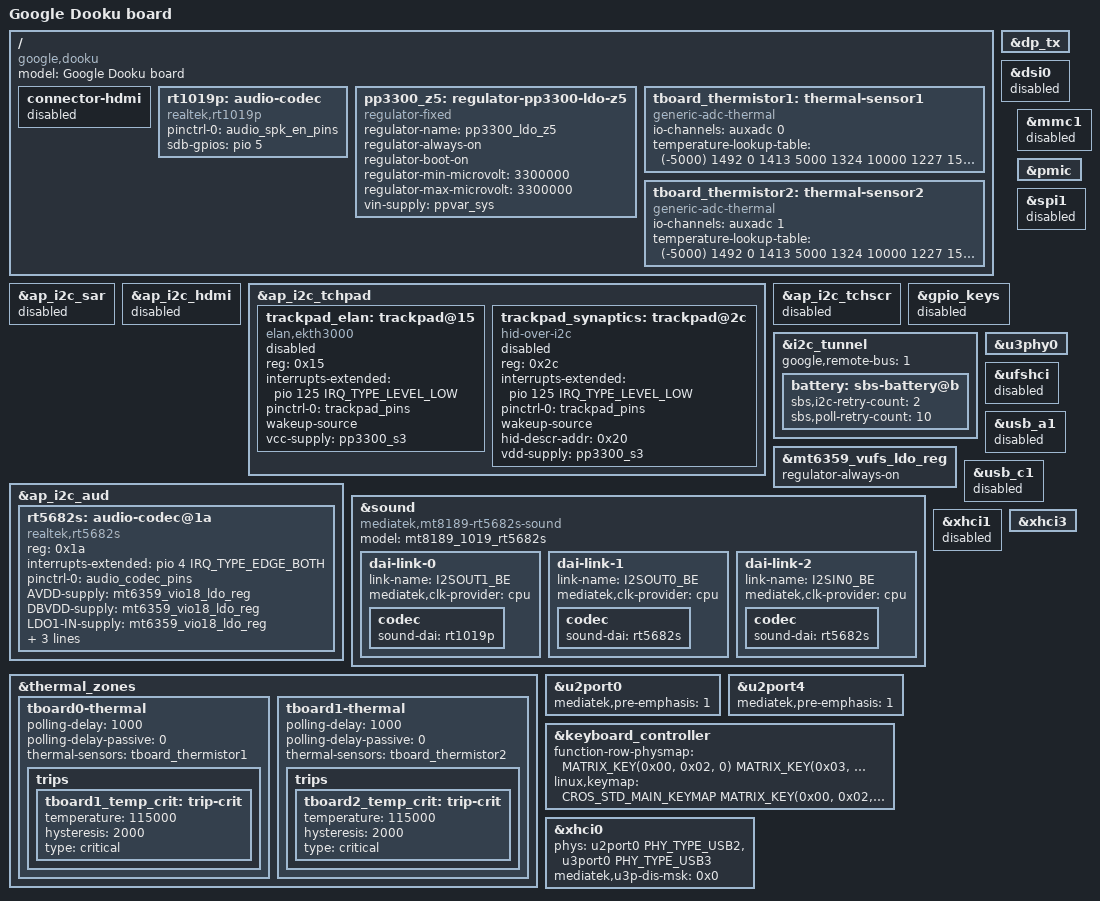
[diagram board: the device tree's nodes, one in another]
// SPDX-License-Identifier: (GPL-2.0 OR MIT)
/*
 * Copyright (C) 2025 Google Inc.
 */
/dts-v1/;
#include "mt8189-skywalker.dtsi"

/ {
	model = "Google Dooku board";
	compatible = "google,dooku", "mediatek,mt8189";

	connector-hdmi {
		status = "disabled";
	};

	/delete-node/ rt9123;

	rt1019p: audio-codec {
		compatible = "realtek,rt1019p";
		#sound-dai-cells = <0>;
		pinctrl-names = "default";
		pinctrl-0 = <&audio_spk_en_pins>;
		sdb-gpios = <&pio 5 GPIO_ACTIVE_HIGH>;
	};

	/* system wide LDO 3.3V power rail */
	pp3300_z5: regulator-pp3300-ldo-z5 {
		compatible = "regulator-fixed";
		regulator-name = "pp3300_ldo_z5";
		regulator-always-on;
		regulator-boot-on;
		regulator-min-microvolt = <3300000>;
		regulator-max-microvolt = <3300000>;
		vin-supply = <&ppvar_sys>;
	};

	tboard_thermistor1: thermal-sensor1 {
		compatible = "generic-adc-thermal";
		#thermal-sensor-cells = <0>;
		io-channels = <&auxadc 0>;
		io-channel-names = "sensor-channel";
		temperature-lookup-table = <    (-5000) 1492
						0 1413
						5000 1324
						10000 1227
						15000 1121
						20000 1017
						25000 900
						30000 797
						35000 698
						40000 606
						45000 522
						50000 449
						55000 383
						60000 327
						65000 278
						70000 236
						75000 201
						80000 171
						85000 145
						90000 163
						95000 124
						100000 91
						105000 78
						110000 67
						115000 58
						120000 50
						125000 44>;
	};

	tboard_thermistor2: thermal-sensor2 {
		compatible = "generic-adc-thermal";
		#thermal-sensor-cells = <0>;
		io-channels = <&auxadc 1>;
		io-channel-names = "sensor-channel";
		temperature-lookup-table = <    (-5000) 1492
						0 1413
						5000 1324
						10000 1227
						15000 1121
						20000 1017
						25000 900
						30000 797
						35000 698
						40000 606
						45000 522
						50000 449
						55000 383
						60000 327
						65000 278
						70000 236
						75000 201
						80000 171
						85000 145
						90000 163
						95000 124
						100000 91
						105000 78
						110000 67
						115000 58
						120000 50
						125000 44>;
	};
};

&ap_i2c_sar {
	status = "disabled";
};

&ap_i2c_hdmi {
	status = "disabled";
};

&ap_i2c_tchpad {
	/delete-node/ trackpad@15;

	trackpad_elan: trackpad@15 {
		compatible = "elan,ekth3000";
		reg = <0x15>;
		interrupts-extended = <&pio 125 IRQ_TYPE_LEVEL_LOW>;
		pinctrl-names = "default";
		pinctrl-0 = <&trackpad_pins>;
		wakeup-source;
		vcc-supply = <&pp3300_s3>;
		status = "fail-needs-probe";
	};

	trackpad_synaptics: trackpad@2c  {
		compatible = "hid-over-i2c";
		reg = <0x2c>;
		interrupts-extended = <&pio 125 IRQ_TYPE_LEVEL_LOW>;
		pinctrl-names = "default";
		pinctrl-0 = <&trackpad_pins>;
		wakeup-source;
		hid-descr-addr = <0x20>;
		vdd-supply = <&pp3300_s3>;
		status = "fail-needs-probe";
	};
};

&ap_i2c_tchscr {
	status = "disabled";

	/delete-node/ touchscreen@41;
};

&dp_tx {
	/delete-property/ mediatek,phy-flip-gpios;
};

&dsi0 {
	status = "disabled";
};

&ap_i2c_aud {
	/delete-node/ audio-codec@1a;

	rt5682s: audio-codec@1a {
		compatible = "realtek,rt5682s";
		reg = <0x1a>;
		interrupts-extended = <&pio 4 IRQ_TYPE_EDGE_BOTH>;
		pinctrl-names = "default";
		pinctrl-0 = <&audio_codec_pins>;
		#sound-dai-cells = <0>;

		AVDD-supply = <&mt6359_vio18_ldo_reg>;
		DBVDD-supply = <&mt6359_vio18_ldo_reg>;
		LDO1-IN-supply = <&mt6359_vio18_ldo_reg>;
		MICVDD-supply = <&pp3300_z1>;
		VBAT-supply = <&pp3300_z5>;
		realtek,jd-src = <1>;
	};
};

&gpio_keys {
	status = "disabled";
};

&i2c_tunnel {
	google,remote-bus = <1>;
	battery: sbs-battery@b {
		sbs,i2c-retry-count = <2>;
		sbs,poll-retry-count = <10>;
	};
};

&mmc1 {
	status = "disabled";
};

&mt6359_vufs_ldo_reg {
	regulator-always-on;
};

&pmic {
	/delete-node/ mt6359codec;
};

&sound {
	compatible = "mediatek,mt8189-rt5682s-sound";
	model = "mt8189_1019_rt5682s";
	status = "okay";

	dai-link-0 {
		link-name = "I2SOUT1_BE";
		mediatek,clk-provider = "cpu";

		codec {
			sound-dai = <&rt1019p>;
		};
	};

	dai-link-1 {
		link-name = "I2SOUT0_BE";
		mediatek,clk-provider = "cpu";

		codec {
			sound-dai = <&rt5682s>;
		};
	};

	dai-link-2 {
		link-name = "I2SIN0_BE";
		mediatek,clk-provider = "cpu";

		codec {
			sound-dai = <&rt5682s>;
		};
	};

	/* delete dai-link-6 because remove hdmi bridge */
	/delete-node/ dai-link-6;
};

&spi1 {
	status = "disabled";
};

&thermal_zones {
	tboard0-thermal {
		polling-delay = <1000>; /* milliseconds */
		polling-delay-passive = <0>; /* milliseconds */
		thermal-sensors = <&tboard_thermistor1>;

		trips {
			tboard1_temp_crit: trip-crit {
				temperature = <115000>;
				hysteresis = <2000>;
				type = "critical";
			};
		};
	};

	tboard1-thermal {
		polling-delay = <1000>; /* milliseconds */
		polling-delay-passive = <0>; /* milliseconds */
		thermal-sensors = <&tboard_thermistor2>;

		trips {
			tboard2_temp_crit: trip-crit {
				temperature = <115000>;
				hysteresis = <2000>;
				type = "critical";
			};
		};
	};
};

&u2port0 {
	mediatek,pre-emphasis = <1>;
};

&u2port4 {
	mediatek,pre-emphasis = <1>;
};

&u3phy0 {
	status = "okay";
};

&ufshci {
	status = "disabled";
};

&usb_a1 {
	status = "disabled";
};

&usb_c1 {
	status = "disabled";
};

&keyboard_controller {
	function-row-physmap = <
		MATRIX_KEY(0x00, 0x02, 0)        /* T1 */
		MATRIX_KEY(0x03, 0x02, 0)        /* T2 */
		MATRIX_KEY(0x02, 0x02, 0)        /* T3 */
		MATRIX_KEY(0x01, 0x02, 0)        /* T4 */
		MATRIX_KEY(0x03, 0x04, 0)        /* T5 */
		MATRIX_KEY(0x02, 0x04, 0)        /* T6 */
		MATRIX_KEY(0x01, 0x04, 0)        /* T7 */
		MATRIX_KEY(0x02, 0x09, 0)        /* T8 */
		MATRIX_KEY(0x01, 0x09, 0)        /* T9 */
		MATRIX_KEY(0x00, 0x04, 0)        /* T10 */
		MATRIX_KEY(0x00, 0x01, 0)        /* T11 */
		MATRIX_KEY(0x01, 0x05, 0)        /* T12 */
		MATRIX_KEY(0x03, 0x05, 0)        /* T13 */
	>;
	linux,keymap = <
		CROS_STD_MAIN_KEYMAP
		MATRIX_KEY(0x00, 0x02, KEY_BACK)           /* T1 */
		MATRIX_KEY(0x03, 0x02, KEY_REFRESH)        /* T2 */
		MATRIX_KEY(0x02, 0x02, KEY_ZOOM)           /* T3 */
		MATRIX_KEY(0x01, 0x02, KEY_SCALE)          /* T4 */
		MATRIX_KEY(0x03, 0x04, KEY_SYSRQ)          /* T5 */
		MATRIX_KEY(0x02, 0x04, KEY_BRIGHTNESSDOWN) /* T6 */
		MATRIX_KEY(0x01, 0x04, KEY_BRIGHTNESSUP)   /* T7 */
		MATRIX_KEY(0x02, 0x09, KEY_PLAYPAUSE)      /* T8 */
		MATRIX_KEY(0x01, 0x09, KEY_MICMUTE)        /* T9 */
		MATRIX_KEY(0x00, 0x04, KEY_MUTE)           /* T10 */
		MATRIX_KEY(0x00, 0x01, KEY_VOLUMEDOWN)     /* T11 */
		MATRIX_KEY(0x01, 0x05, KEY_VOLUMEUP)       /* T12 */
		MATRIX_KEY(0x03, 0x05, KEY_CONTROLPANEL)   /* T13 */
		MATRIX_KEY(0x03, 0x00, KEY_LEFTMETA)       /* Search*/
		MATRIX_KEY(0x01, 0x0e, KEY_LEFTCTRL)       /* Left Control*/
		MATRIX_KEY(0x06, 0x0d, KEY_BACKSLASH)      /* KEY_BACKSLASH*/
		MATRIX_KEY(0x03, 0x0e, KEY_RIGHTCTRL)      /* Right Control*/
		MATRIX_KEY(0x06, 0x0a, KEY_LEFTALT)        /* KEY_LEFTALT*/
	>;
};

&xhci0 {
	phys = <&u2port0 PHY_TYPE_USB2>,
		<&u3port0 PHY_TYPE_USB3>;
	mediatek,u3p-dis-msk = <0x0>;
	status = "okay";
};

&xhci1 {
	status = "disabled";
};

/*This is a workaround; Disabling the node doesn't work.*/
&xhci3 {
	/delete-node/ hub@1;
	/delete-node/ hub@2;
};
